AUTOSAR XML (schema 4-0-3)
package /ComponentTypes
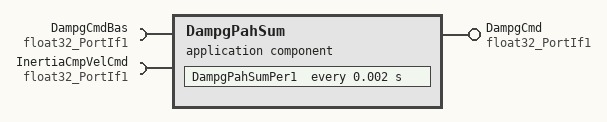
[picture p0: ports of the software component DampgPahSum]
  application sw component type DampgPahSum
    provide port DampgCmd: nonqueued-sender-com-spec{data-element=Val, init-value=0}, provided-interface=float32_PortIf1
    require port DampgCmdBas: nonqueued-receiver-com-spec{data-element=Val, filter=data-filter-type=ALWAYS, init-value=0}, required-interface=float32_PortIf1
    require port InertiaCmpVelCmd: nonqueued-receiver-com-spec{data-element=Val, filter=data-filter-type=ALWAYS, init-value=0}, required-interface=float32_PortIf1
    behavior DampgPahSum_InternalBehavior
      timing event TMT_DampgPahSumPer1: start-on-event=DampgPahSumPer1, period=0.002
      port-api-options:
        enable-take-address=false, indirect-api=false, port=DampgCmd
        enable-take-address=false, indirect-api=false, port=DampgCmdBas
        enable-take-address=false, indirect-api=false, port=InertiaCmpVelCmd
      runnable DampgPahSumPer1
        data-receive-point-by-arguments:
          access REC_DampgCmdBas_Val_1: accessed-variable=DampgCmdBas.Val
          access REC_InertiaCmpVelCmd_Val_1: accessed-variable=InertiaCmpVelCmd.Val
        data-send-points:
          access SEND_DampgCmd_Val_1: accessed-variable=DampgCmd.Val
  swc implementation DampgPahSum_Implementation: behavior=DampgPahSum_InternalBehavior
    code-descriptors:
      code Default: artifact-descriptors=autosar-engineering-object={short-label=Default, category=SWSRC}
